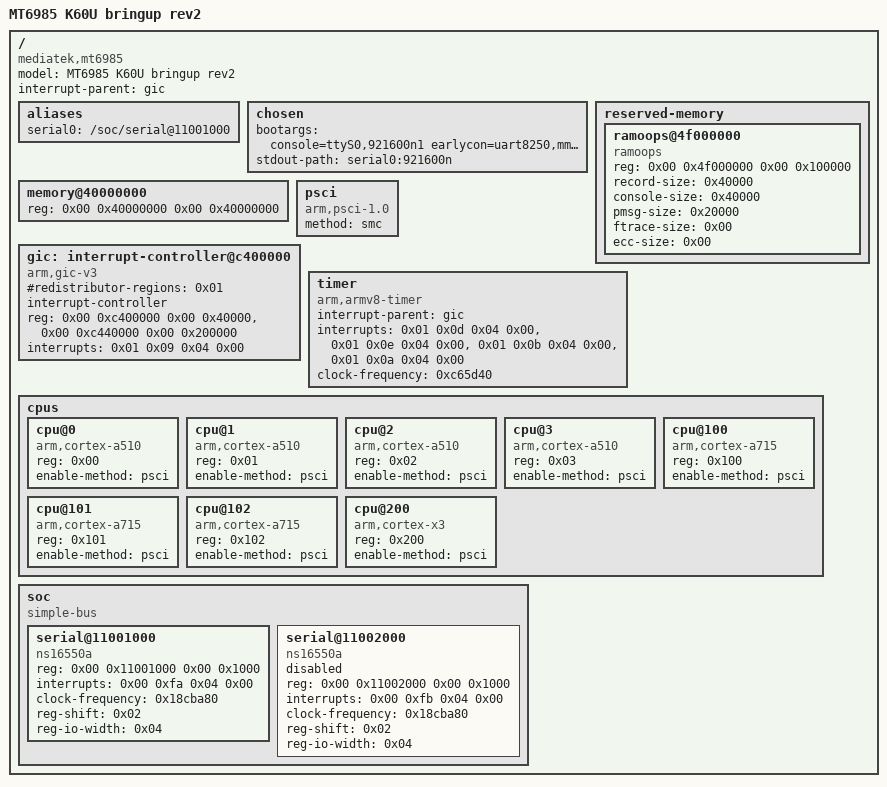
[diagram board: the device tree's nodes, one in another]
// SPDX-License-Identifier: (GPL-2.0+ OR MIT)
/*
 * Redmi K60 Ultra (MT6985 / corot) — Linux 6.1 bring-up device tree  (rev2)
 *
 * rev2 关键修改:
 *   1. 去掉 init=/bin/sh —— 无 ramdisk 内 shell 时会触发
 *      "Kernel panic - not syncing: No working init found" 自我重启死循环
 *   2. 新增 reserved-memory / ramoops —— 内核崩溃日志落内存，熬过重启，
 *      回原系统后可从 /sys/fs/pstore 读（需 CONFIG_PSTORE_RAM=y）
 *   3. 不再强制指定 init，交给 ramdisk 自动探测
 *   4. panic=0 —— panic 后不自动重启，便于观察（真机无串口时靠 ramoops）
 */

/dts-v1/;

/ {
	model = "MT6985 K60U bringup rev2";
	compatible = "mediatek,mt6985", "xiaomi,corot";
	interrupt-parent = <&gic>;
	#address-cells = <0x02>;
	#size-cells = <0x02>;

	aliases {
		serial0 = "/soc/serial@11001000";
	};

	chosen {
		bootargs = "console=ttyS0,921600n1 earlycon=uart8250,mmio32,0x11001000,921600n1 loglevel=8 ignore_loglevel clk_ignore_unused pd_ignore_unused panic=0";
		stdout-path = "serial0:921600n";
	};

	/*
	 * 崩溃日志区：1 MB @ 0x4F000000（首个 1GB bank 尾部，由 reserved-memory 排除）
	 * 布局: console 256K | pmsg 128K | record 256K
	 */
	reserved-memory {
		#address-cells = <0x02>;
		#size-cells = <0x02>;
		ranges;

		ramoops@4f000000 {
			compatible = "ramoops";
			reg = <0x00 0x4f000000 0x00 0x100000>;
			record-size = <0x40000>;
			console-size = <0x40000>;
			pmsg-size = <0x20000>;
			ftrace-size = <0x00>;
			ecc-size = <0x00>;
		};
	};

	memory@40000000 {
		device_type = "memory";
		reg = <0x00 0x40000000 0x00 0x40000000>;
	};

	psci {
		compatible = "arm,psci-1.0";
		method = "smc";
	};

	gic: interrupt-controller@c400000 {
		compatible = "arm,gic-v3";
		#interrupt-cells = <0x04>;
		#address-cells = <0x02>;
		#size-cells = <0x02>;
		#redistributor-regions = <0x01>;
		interrupt-controller;
		reg = <0x00 0xc400000 0x00 0x40000>,
		      <0x00 0xc440000 0x00 0x200000>;
		interrupts = <0x01 0x09 0x04 0x00>;
	};

	timer {
		compatible = "arm,armv8-timer";
		interrupt-parent = <&gic>;
		interrupts = <0x01 0x0d 0x04 0x00>,
			     <0x01 0x0e 0x04 0x00>,
			     <0x01 0x0b 0x04 0x00>,
			     <0x01 0x0a 0x04 0x00>;
		clock-frequency = <0xc65d40>;
	};

	cpus {
		#address-cells = <0x01>;
		#size-cells = <0x00>;

		cpu@0 {
			device_type = "cpu";
			compatible = "arm,cortex-a510";
			reg = <0x00>;
			enable-method = "psci";
		};
		cpu@1 {
			device_type = "cpu";
			compatible = "arm,cortex-a510";
			reg = <0x01>;
			enable-method = "psci";
		};
		cpu@2 {
			device_type = "cpu";
			compatible = "arm,cortex-a510";
			reg = <0x02>;
			enable-method = "psci";
		};
		cpu@3 {
			device_type = "cpu";
			compatible = "arm,cortex-a510";
			reg = <0x03>;
			enable-method = "psci";
		};
		cpu@100 {
			device_type = "cpu";
			compatible = "arm,cortex-a715";
			reg = <0x100>;
			enable-method = "psci";
		};
		cpu@101 {
			device_type = "cpu";
			compatible = "arm,cortex-a715";
			reg = <0x101>;
			enable-method = "psci";
		};
		cpu@102 {
			device_type = "cpu";
			compatible = "arm,cortex-a715";
			reg = <0x102>;
			enable-method = "psci";
		};
		cpu@200 {
			device_type = "cpu";
			compatible = "arm,cortex-x3";
			reg = <0x200>;
			enable-method = "psci";
		};
	};

	soc {
		compatible = "simple-bus";
		#address-cells = <0x02>;
		#size-cells = <0x02>;
		ranges;

		serial@11001000 {
			compatible = "ns16550a";
			reg = <0x00 0x11001000 0x00 0x1000>;
			interrupts = <0x00 0xfa 0x04 0x00>;
			clock-frequency = <0x18cba80>;
			reg-shift = <0x02>;
			reg-io-width = <0x04>;
			status = "okay";
		};

		serial@11002000 {
			compatible = "ns16550a";
			reg = <0x00 0x11002000 0x00 0x1000>;
			interrupts = <0x00 0xfb 0x04 0x00>;
			clock-frequency = <0x18cba80>;
			reg-shift = <0x02>;
			reg-io-width = <0x04>;
			status = "disabled";
		};
	};
};
